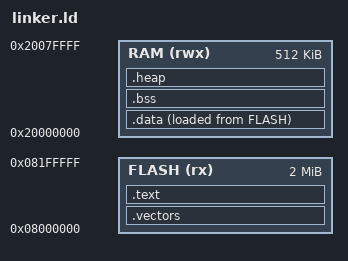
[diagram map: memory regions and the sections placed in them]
ENTRY(Reset_Handler)

MEMORY
{
    FLASH (rx)  : ORIGIN = 0x08000000, LENGTH = 2M
    RAM   (rwx) : ORIGIN = 0x20000000, LENGTH = 512K
}

_estack = ORIGIN(RAM) + LENGTH(RAM);
_sidata = LOADADDR(.data);

PHDRS
{
    text PT_LOAD FLAGS(5);
    data PT_LOAD FLAGS(6);
}

SECTIONS
{
    .vectors ORIGIN(FLASH) :
    {
        KEEP(*(.vectors))
    } > FLASH :text

    .text :
    {
        *(.text*)
        *(.rodata*)
        KEEP(*(.init))
        KEEP(*(.fini))
        *(.ARM.extab*)
        *(.ARM.exidx*)
    } > FLASH :text

    .data :
    {
        . = ALIGN(8);
        _sdata = .;
        *(.data*)
        . = ALIGN(8);
        _edata = .;
    } > RAM AT > FLASH :data

    .bss (NOLOAD) :
    {
        . = ALIGN(8);
        _sbss = .;
        *(.bss*)
        *(COMMON)
        . = ALIGN(8);
        _ebss = .;
        _end = .;
    } > RAM :NONE

    .heap (NOLOAD) :
    {
        . = ALIGN(8);
        _heap_start = .;
        . += 96K;
        _heap_end = .;
    } > RAM :NONE

    ASSERT(_heap_end < (_estack - 16K), "STM32H563 RAM overflow")
}
